# iostr750 register map
Registers are 16-bit, access not given, no defined reset value unless marked. A register's access mark holds for its fields unless they carry their own. Addresses are absolute; registers are grouped by the start of their names; [hi:lo] are bit positions; {n}, {i} and the like mark numbered series.

## SSP1
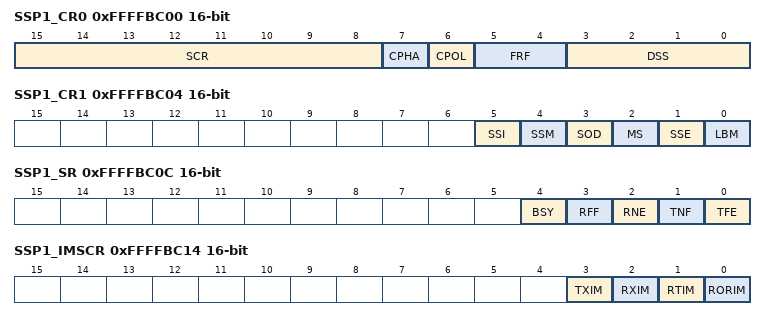
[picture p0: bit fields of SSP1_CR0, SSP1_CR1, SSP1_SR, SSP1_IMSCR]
0xFFFFBC00 SSP1_CR0
  [15:8] SCR, [7] CPHA, [6] CPOL, [5:4] FRF, [3:0] DSS
0xFFFFBC04 SSP1_CR1
  [5] SSI, [4] SSM, [3] SOD, [2] MS, [1] SSE, [0] LBM
0xFFFFBC08 SSP1_DR
0xFFFFBC0C SSP1_SR
  [4] BSY, [3] RFF, [2] RNE, [1] TNF, [0] TFE
0xFFFFBC10 SSP1_PR
  [7:0] CPSDVSR
0xFFFFBC14 SSP1_IMSCR
  [3] TXIM, [2] RXIM, [1] RTIM, [0] RORIM
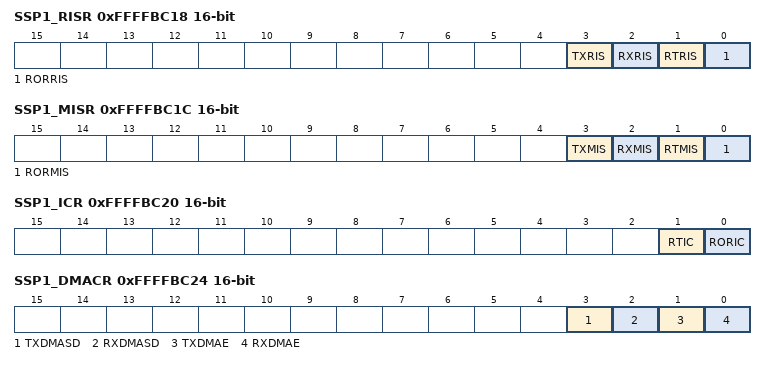
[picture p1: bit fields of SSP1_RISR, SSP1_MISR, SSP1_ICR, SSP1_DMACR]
0xFFFFBC18 SSP1_RISR
  [3] TXRIS, [2] RXRIS, [1] RTRIS, [0] RORRIS
0xFFFFBC1C SSP1_MISR
  [3] TXMIS, [2] RXMIS, [1] RTMIS, [0] RORMIS
0xFFFFBC20 SSP1_ICR
  [1] RTIC, [0] RORIC
0xFFFFBC24 SSP1_DMACR
  [3] TXDMASD, [2] RXDMASD, [1] TXDMAE, [0] RXDMAE

## UART0
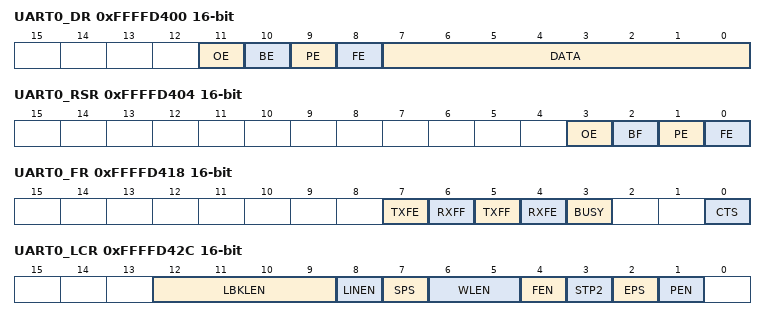
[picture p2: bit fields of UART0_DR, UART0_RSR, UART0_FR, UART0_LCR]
0xFFFFD400 UART0_DR
  [11] OE, [10] BE, [9] PE, [8] FE, [7:0] DATA
0xFFFFD404 UART0_RSR
  [3] OE, [2] BF, [1] PE, [0] FE
0xFFFFD418 UART0_FR
  [7] TXFE, [6] RXFF, [5] TXFF, [4] RXFE, [3] BUSY, [0] CTS
0xFFFFD41C UART0_BKR
  [0] BRK
0xFFFFD424 UART0_IBRD
0xFFFFD428 UART0_FBRD
  [5:0] DIVFRAC
0xFFFFD42C UART0_LCR
  [12:9] LBKLEN, [8] LINEN, [7] SPS, [6:5] WLEN, [4] FEN, [3] STP2, [2] EPS, [1] PEN
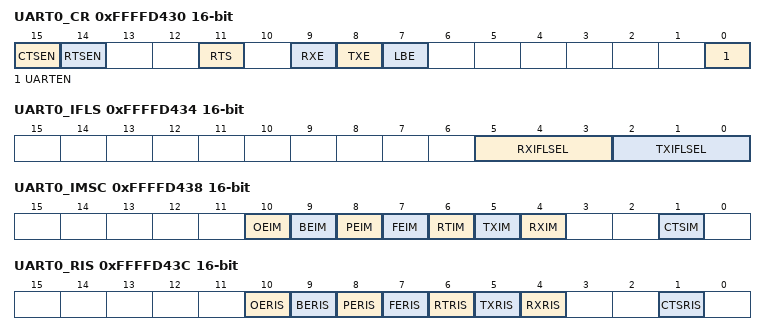
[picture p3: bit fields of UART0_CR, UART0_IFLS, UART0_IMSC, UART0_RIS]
0xFFFFD430 UART0_CR
  [15] CTSEN, [14] RTSEN, [11] RTS, [9] RXE, [8] TXE, [7] LBE, [0] UARTEN
0xFFFFD434 UART0_IFLS
  [5:3] RXIFLSEL, [2:0] TXIFLSEL
0xFFFFD438 UART0_IMSC
  [10] OEIM, [9] BEIM, [8] PEIM, [7] FEIM, [6] RTIM, [5] TXIM, [4] RXIM, [1] CTSIM
0xFFFFD43C UART0_RIS
  [10] OERIS, [9] BERIS, [8] PERIS, [7] FERIS, [6] RTRIS, [5] TXRIS, [4] RXRIS, [1] CTSRIS
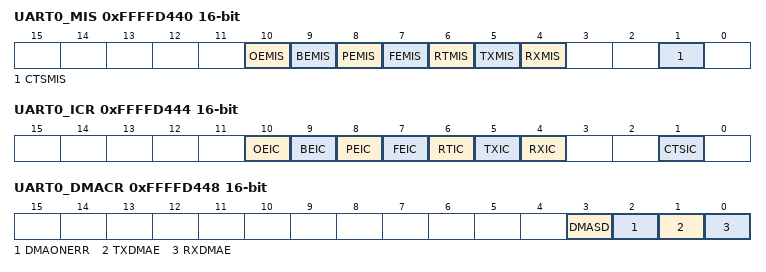
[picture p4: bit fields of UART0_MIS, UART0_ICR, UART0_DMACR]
0xFFFFD440 UART0_MIS
  [10] OEMIS, [9] BEMIS, [8] PEMIS, [7] FEMIS, [6] RTMIS, [5] TXMIS, [4] RXMIS, [1] CTSMIS
0xFFFFD444 UART0_ICR
  [10] OEIC, [9] BEIC, [8] PEIC, [7] FEIC, [6] RTIC, [5] TXIC, [4] RXIC, [1] CTSIC
0xFFFFD448 UART0_DMACR
  [3] DMASD, [2] DMAONERR, [1] TXDMAE, [0] RXDMAE

## UART1
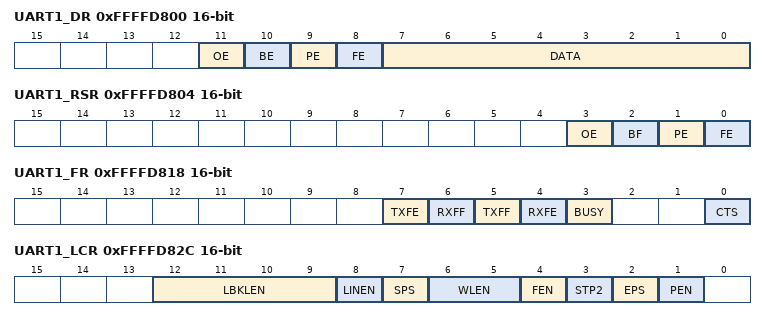
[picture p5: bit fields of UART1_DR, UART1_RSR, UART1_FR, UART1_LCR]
0xFFFFD800 UART1_DR
  [11] OE, [10] BE, [9] PE, [8] FE, [7:0] DATA
0xFFFFD804 UART1_RSR
  [3] OE, [2] BF, [1] PE, [0] FE
0xFFFFD818 UART1_FR
  [7] TXFE, [6] RXFF, [5] TXFF, [4] RXFE, [3] BUSY, [0] CTS
0xFFFFD81C UART1_BKR
  [0] BRK
0xFFFFD824 UART1_IBRD
0xFFFFD828 UART1_FBRD
  [5:0] DIVFRAC
0xFFFFD82C UART1_LCR
  [12:9] LBKLEN, [8] LINEN, [7] SPS, [6:5] WLEN, [4] FEN, [3] STP2, [2] EPS, [1] PEN
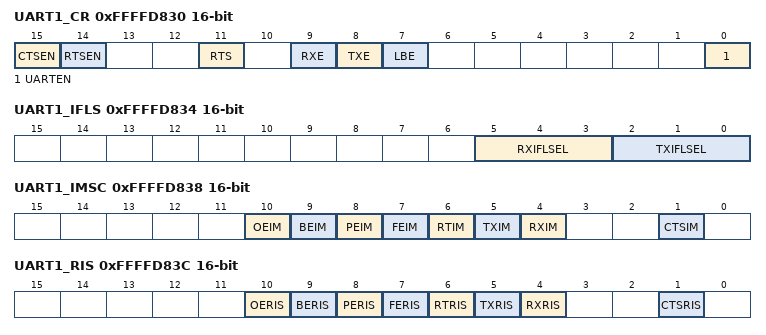
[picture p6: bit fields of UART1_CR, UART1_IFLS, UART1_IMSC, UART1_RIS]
0xFFFFD830 UART1_CR
  [15] CTSEN, [14] RTSEN, [11] RTS, [9] RXE, [8] TXE, [7] LBE, [0] UARTEN
0xFFFFD834 UART1_IFLS
  [5:3] RXIFLSEL, [2:0] TXIFLSEL
0xFFFFD838 UART1_IMSC
  [10] OEIM, [9] BEIM, [8] PEIM, [7] FEIM, [6] RTIM, [5] TXIM, [4] RXIM, [1] CTSIM
0xFFFFD83C UART1_RIS
  [10] OERIS, [9] BERIS, [8] PERIS, [7] FERIS, [6] RTRIS, [5] TXRIS, [4] RXRIS, [1] CTSRIS
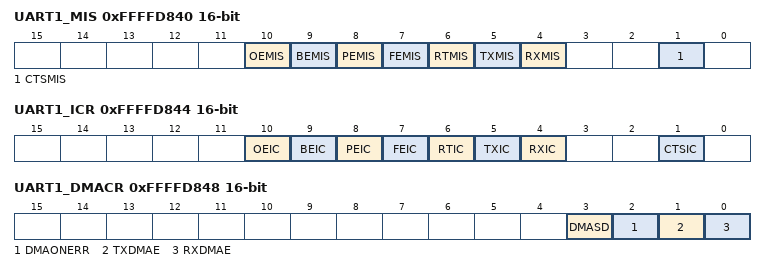
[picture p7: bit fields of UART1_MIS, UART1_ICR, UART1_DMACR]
0xFFFFD840 UART1_MIS
  [10] OEMIS, [9] BEMIS, [8] PEMIS, [7] FEMIS, [6] RTMIS, [5] TXMIS, [4] RXMIS, [1] CTSMIS
0xFFFFD844 UART1_ICR
  [10] OEIC, [9] BEIC, [8] PEIC, [7] FEIC, [6] RTIC, [5] TXIC, [4] RXIC, [1] CTSIC
0xFFFFD848 UART1_DMACR
  [3] DMASD, [2] DMAONERR, [1] TXDMAE, [0] RXDMAE

## UART2
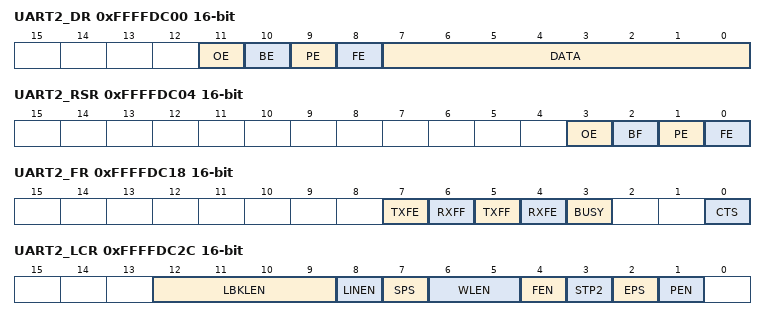
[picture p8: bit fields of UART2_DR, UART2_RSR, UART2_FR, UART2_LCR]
0xFFFFDC00 UART2_DR
  [11] OE, [10] BE, [9] PE, [8] FE, [7:0] DATA
0xFFFFDC04 UART2_RSR
  [3] OE, [2] BF, [1] PE, [0] FE
0xFFFFDC18 UART2_FR
  [7] TXFE, [6] RXFF, [5] TXFF, [4] RXFE, [3] BUSY, [0] CTS
0xFFFFDC1C UART2_BKR
  [0] BRK
0xFFFFDC24 UART2_IBRD
0xFFFFDC28 UART2_FBRD
  [5:0] DIVFRAC
0xFFFFDC2C UART2_LCR
  [12:9] LBKLEN, [8] LINEN, [7] SPS, [6:5] WLEN, [4] FEN, [3] STP2, [2] EPS, [1] PEN
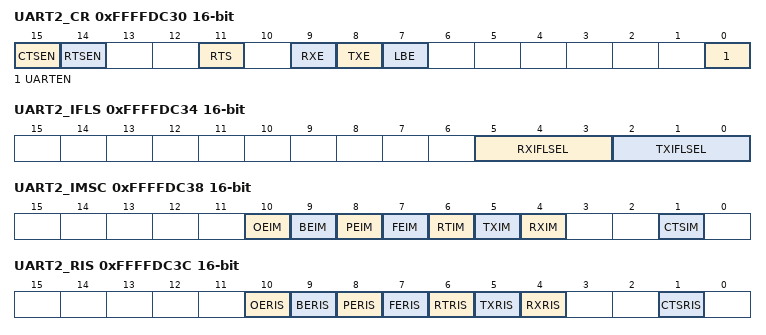
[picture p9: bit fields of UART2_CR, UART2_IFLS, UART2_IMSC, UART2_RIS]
0xFFFFDC30 UART2_CR
  [15] CTSEN, [14] RTSEN, [11] RTS, [9] RXE, [8] TXE, [7] LBE, [0] UARTEN
0xFFFFDC34 UART2_IFLS
  [5:3] RXIFLSEL, [2:0] TXIFLSEL
0xFFFFDC38 UART2_IMSC
  [10] OEIM, [9] BEIM, [8] PEIM, [7] FEIM, [6] RTIM, [5] TXIM, [4] RXIM, [1] CTSIM
0xFFFFDC3C UART2_RIS
  [10] OERIS, [9] BERIS, [8] PERIS, [7] FERIS, [6] RTRIS, [5] TXRIS, [4] RXRIS, [1] CTSRIS
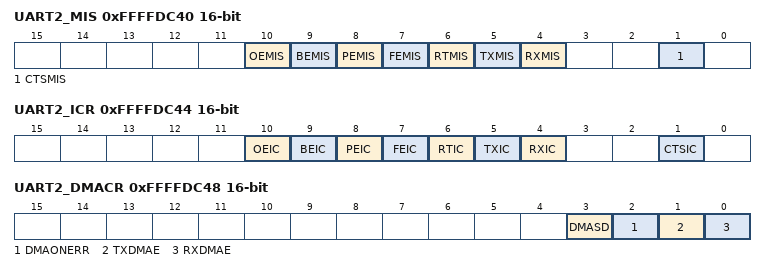
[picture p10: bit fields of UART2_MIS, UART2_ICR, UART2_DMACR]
0xFFFFDC40 UART2_MIS
  [10] OEMIS, [9] BEMIS, [8] PEMIS, [7] FEMIS, [6] RTMIS, [5] TXMIS, [4] RXMIS, [1] CTSMIS
0xFFFFDC44 UART2_ICR
  [10] OEIC, [9] BEIC, [8] PEIC, [7] FEIC, [6] RTIC, [5] TXIC, [4] RXIC, [1] CTSIC
0xFFFFDC48 UART2_DMACR
  [3] DMASD, [2] DMAONERR, [1] TXDMAE, [0] RXDMAE

## USB
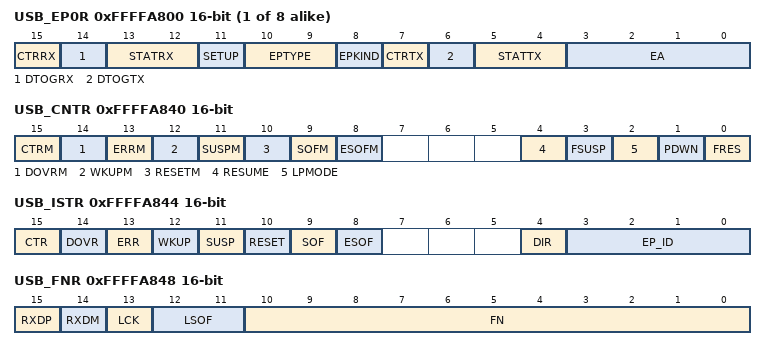
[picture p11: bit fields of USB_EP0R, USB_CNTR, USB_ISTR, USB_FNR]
{0xFFFFA800+4i} USB_EP{i}R (i=0..7)
  [15] CTRRX, [14] DTOGRX, [13:12] STATRX, [11] SETUP, [10:9] EPTYPE, [8] EPKIND, [7] CTRTX, [6] DTOGTX, [5:4] STATTX, [3:0] EA
0xFFFFA840 USB_CNTR
  [15] CTRM, [14] DOVRM, [13] ERRM, [12] WKUPM, [11] SUSPM, [10] RESETM, [9] SOFM, [8] ESOFM, [4] RESUME, [3] FSUSP, [2] LPMODE, [1] PDWN, [0] FRES
0xFFFFA844 USB_ISTR
  [15] CTR, [14] DOVR, [13] ERR, [12] WKUP, [11] SUSP, [10] RESET, [9] SOF, [8] ESOF, [4] DIR, [3:0] EP_ID
0xFFFFA848 USB_FNR
  [15] RXDP, [14] RXDM, [13] LCK, [12:11] LSOF, [10:0] FN
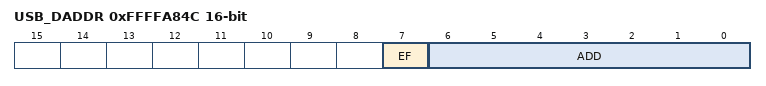
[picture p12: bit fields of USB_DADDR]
0xFFFFA84C USB_DADDR
  [7] EF, [6:0] ADD
0xFFFFA850 USB_BTABLE

## ADC
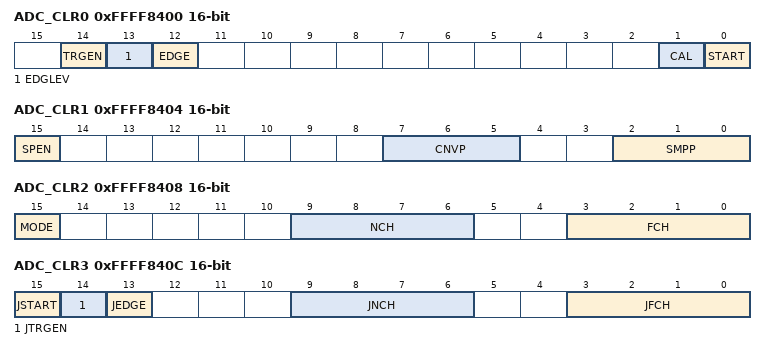
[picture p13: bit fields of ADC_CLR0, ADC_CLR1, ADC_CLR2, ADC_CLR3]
0xFFFF8400 ADC_CLR0
  [14] TRGEN, [13] EDGLEV, [12] EDGE, [1] CAL, [0] START
0xFFFF8404 ADC_CLR1
  [15] SPEN, [7:5] CNVP, [2:0] SMPP
0xFFFF8408 ADC_CLR2
  [15] MODE, [9:6] NCH, [3:0] FCH
0xFFFF840C ADC_CLR3
  [15] JSTART, [14] JTRGEN, [13] JEDGE, [9:6] JNCH, [3:0] JFCH
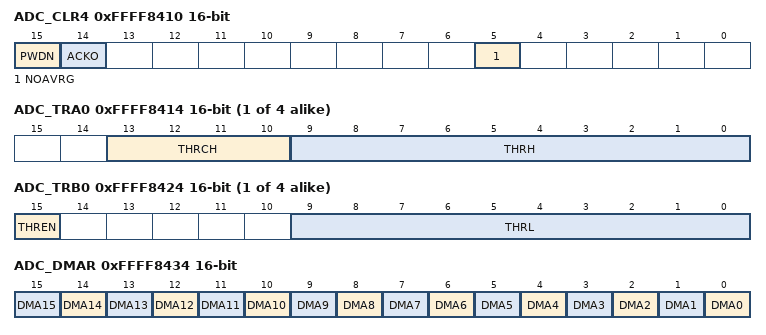
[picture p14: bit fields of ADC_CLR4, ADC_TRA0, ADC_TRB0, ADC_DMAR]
0xFFFF8410 ADC_CLR4
  [15] PWDN, [14] ACKO, [5] NOAVRG
{0xFFFF8414+4i} ADC_TRA{i} (i=0..3)
  [13:10] THRCH, [9:0] THRH
{0xFFFF8424+4i} ADC_TRB{i} (i=0..3)
  [15] THREN, [9:0] THRL
0xFFFF8434 ADC_DMAR
  [n] DMA{n} (n=0..15)
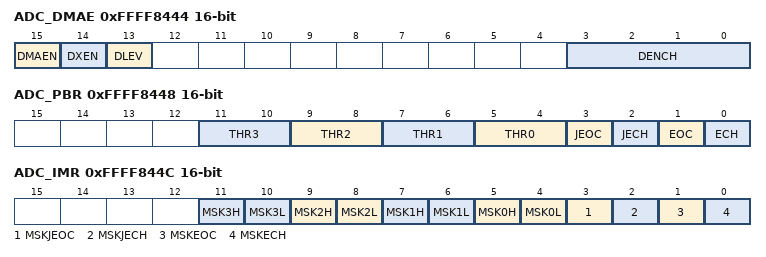
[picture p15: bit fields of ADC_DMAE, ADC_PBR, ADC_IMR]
0xFFFF8444 ADC_DMAE
  [15] DMAEN, [14] DXEN, [13] DLEV, [3:0] DENCH
0xFFFF8448 ADC_PBR
  [2n+5:2n+4] THR{n} (n=0..3), [3] JEOC, [2] JECH, [1] EOC, [0] ECH
0xFFFF844C ADC_IMR
  [2n+5] MSK{n}H (n=0..3), [2n+4] MSK{n}L (n=0..3), [3] MSKJEOC, [2] MSKJECH, [1] MSKEOC, [0] MSKECH
{0xFFFF8450+4i} ADC_D{i} (i=0..15)
  [9:0] CDATA

## FLASH
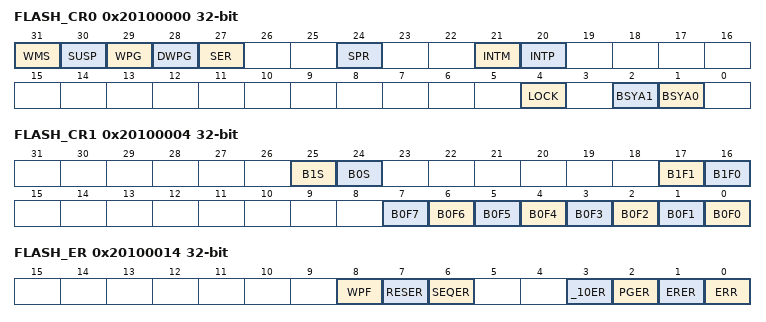
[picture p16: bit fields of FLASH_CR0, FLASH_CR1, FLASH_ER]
0x20100000 FLASH_CR0 32-bit
  [31] WMS, [30] SUSP, [29] WPG, [28] DWPG, [27] SER, [24] SPR, [21] INTM, [20] INTP, [4] LOCK, [2] BSYA1, [1] BSYA0
0x20100004 FLASH_CR1 32-bit
  [25] B1S, [24] B0S, [17] B1F1, [16] B1F0, [n] B0F{n} (n=0..7)
0x20100008 FLASH_DR0 32-bit
0x2010000C FLASH_DR1 32-bit
0x20100010 FLASH_AR 32-bit
  [20:0] ADD
0x20100014 FLASH_ER 32-bit
  [8] WPF, [7] RESER, [6] SEQER, [3] _10ER, [2] PGER, [1] ERER, [0] ERR
0x2010DFB0 FLASH_NVWPAR 32-bit
  [17:16] W1P, [7:0] W0P
0x2010DFB8 FLASH_NVAPR0 32-bit
  [0] READOUT
0x2010DFBC FLASH_NVAPR1 32-bit
  [31:16] PEN, [15:0] PDS

## SFR
0x60000010 CFG_GLCONF 32-bit
  [31:16] DEVICEID, [9] USB_FILTEN, [8] FLASH_BURST, [7] FLASH_BUSY, [1:0] SW_BOOT
